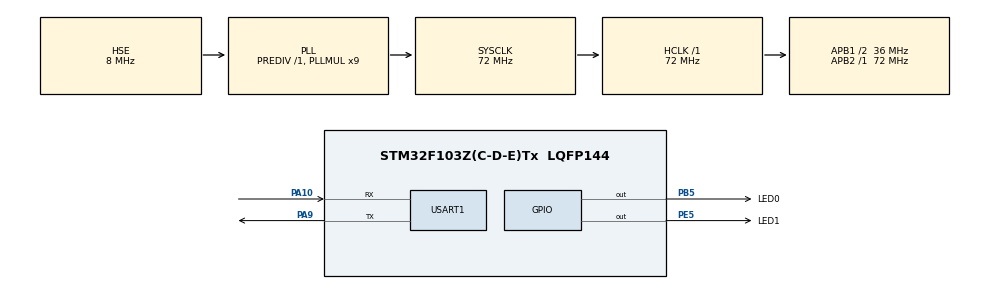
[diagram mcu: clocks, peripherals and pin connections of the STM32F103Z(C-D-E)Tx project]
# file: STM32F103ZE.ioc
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FREERTOS.Tasks01=Task_LED0,0,128,Func_LED0,Default,NULL,Dynamic,NULL,NULL;Task_LED1,-3,128,Func_LED1,Default,NULL,Dynamic,NULL,NULL
Mcu.Family=STM32F1
Mcu.Name=STM32F103Z(C-D-E)Tx
Mcu.Package=LQFP144
NVIC.FLASH_IRQn=true\:5\:0\:false\:true\:true\:1\:true\:true
NVIC.PVD_IRQn=true\:5\:0\:false\:true\:true\:4\:true\:true
NVIC.PriorityGroup=NVIC_PRIORITYGROUP_4
NVIC.RCC_IRQn=true\:5\:0\:true\:true\:true\:2\:true\:true
NVIC.TIM8_UP_IRQn=true\:0\:0\:false\:false\:true\:false\:false
NVIC.TimeBase=TIM8_UP_IRQn
NVIC.TimeBaseIP=TIM8
NVIC.USART1_IRQn=true\:5\:0\:false\:true\:true\:3\:true\:true
OSC_IN.Mode=HSE-External-Oscillator
OSC_IN.Signal=RCC_OSC_IN
OSC_OUT.Mode=HSE-External-Oscillator
OSC_OUT.Signal=RCC_OSC_OUT
PA10.Mode=Asynchronous
PA10.Signal=USART1_RX
PA13.Mode=Serial_Wire
PA13.Signal=SYS_JTMS-SWDIO
PA14.Mode=Serial_Wire
PA14.Signal=SYS_JTCK-SWCLK
PA9.Mode=Asynchronous
PA9.Signal=USART1_TX
PB5.GPIO_Label=LED0
PB5.GPIO_Speed=GPIO_SPEED_FREQ_LOW
PB5.Signal=GPIO_Output
PC14-OSC32_IN.Mode=LSE-External-Oscillator
PC14-OSC32_IN.Signal=RCC_OSC32_IN
PC15-OSC32_OUT.Mode=LSE-External-Oscillator
PC15-OSC32_OUT.Signal=RCC_OSC32_OUT
PE5.GPIO_Label=LED1
PE5.Signal=GPIO_Output
ProjectManager.HeapSize=0x200
ProjectManager.StackSize=0x400
ProjectManager.TargetToolchain=MDK-ARM V5
RCC.AHBFreq_Value=72000000
RCC.APB1CLKDivider=RCC_HCLK_DIV2
RCC.APB1Freq_Value=36000000
RCC.APB1TimFreq_Value=72000000
RCC.APB2Freq_Value=72000000
RCC.APB2TimFreq_Value=72000000
RCC.HCLKFreq_Value=72000000
RCC.PLLMUL=RCC_PLL_MUL9
RCC.PLLSourceVirtual=RCC_PLLSOURCE_HSE
RCC.SYSCLKFreq_VALUE=72000000
RCC.SYSCLKSource=RCC_SYSCLKSOURCE_PLLCLK
RCC.USBFreq_Value=72000000
USART1.VirtualMode=VM_ASYNC
VP_FREERTOS_VS_ENABLE.Mode=Enabled
VP_SYS_VS_tim8.Mode=TIM8
board=custom

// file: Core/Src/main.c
/* USER CODE BEGIN Header */
/**
  ******************************************************************************
  * @file           : main.c
  * @brief          : Main program body
  ******************************************************************************
  ** This notice applies to any and all portions of this file
  * that are not between comment pairs USER CODE BEGIN and
  * USER CODE END. Other portions of this file, whether
  * inserted by the user or by software development tools
  * are owned by their respective copyright owners.
  *
  * COPYRIGHT(c) 2019 STMicroelectronics
  *
  * Redistribution and use in source and binary forms, with or without modification,
  * are permitted provided that the following conditions are met:
  *   1. Redistributions of source code must retain the above copyright notice,
  *      this list of conditions and the following disclaimer.
  *   2. Redistributions in binary form must reproduce the above copyright notice,
  *      this list of conditions and the following disclaimer in the documentation
  *      and/or other materials provided with the distribution.
  *   3. Neither the name of STMicroelectronics nor the names of its contributors
  *      may be used to endorse or promote products derived from this software
  *      without specific prior written permission.
  *
  * THIS SOFTWARE IS PROVIDED BY THE COPYRIGHT HOLDERS AND CONTRIBUTORS "AS IS"
  * AND ANY EXPRESS OR IMPLIED WARRANTIES, INCLUDING, BUT NOT LIMITED TO, THE
  * IMPLIED WARRANTIES OF MERCHANTABILITY AND FITNESS FOR A PARTICULAR PURPOSE ARE
  * DISCLAIMED. IN NO EVENT SHALL THE COPYRIGHT HOLDER OR CONTRIBUTORS BE LIABLE
  * FOR ANY DIRECT, INDIRECT, INCIDENTAL, SPECIAL, EXEMPLARY, OR CONSEQUENTIAL
  * DAMAGES (INCLUDING, BUT NOT LIMITED TO, PROCUREMENT OF SUBSTITUTE GOODS OR
  * SERVICES; LOSS OF USE, DATA, OR PROFITS; OR BUSINESS INTERRUPTION) HOWEVER
  * CAUSED AND ON ANY THEORY OF LIABILITY, WHETHER IN CONTRACT, STRICT LIABILITY,
  * OR TORT (INCLUDING NEGLIGENCE OR OTHERWISE) ARISING IN ANY WAY OUT OF THE USE
  * OF THIS SOFTWARE, EVEN IF ADVISED OF THE POSSIBILITY OF SUCH DAMAGE.
  *
  ******************************************************************************
  */
/* USER CODE END Header */

#include "main.h"
#include "cmsis_os.h"
#include "usart.h"
#include "gpio.h"

void SystemClock_Config(void);
void MX_FREERTOS_Init(void);
static void MX_NVIC_Init(void);

int main(void)
{

  /* MCU Configuration--------------------------------------------------------*/

  /* Reset of all peripherals, Initializes the Flash interface and the Systick. */
  HAL_Init();

  /* Configure the system clock */
  SystemClock_Config();

  /* Initialize all configured peripherals */
  MX_GPIO_Init();
  MX_USART1_UART_Init();

  /* Initialize interrupts */
  MX_NVIC_Init();
  /* USER CODE BEGIN 2 */
	HAL_UART_Receive_IT(&huart1,&Buffer_huart1[0],1);
  /* USER CODE END 2 */

  /* Call init function for freertos objects (in freertos.c) */
  MX_FREERTOS_Init();

  /* Start scheduler */
  osKernelStart();

  /* We should never get here as control is now taken by the scheduler */

  /* Infinite loop */
  while (1)
  {

  }
}

void SystemClock_Config(void)
{
  RCC_OscInitTypeDef RCC_OscInitStruct = {0};
  RCC_ClkInitTypeDef RCC_ClkInitStruct = {0};

  /**Initializes the CPU, AHB and APB busses clocks
  */
  RCC_OscInitStruct.OscillatorType = RCC_OSCILLATORTYPE_HSE;
  RCC_OscInitStruct.HSEState = RCC_HSE_ON;
  RCC_OscInitStruct.HSEPredivValue = RCC_HSE_PREDIV_DIV1;
  RCC_OscInitStruct.HSIState = RCC_HSI_ON;
  RCC_OscInitStruct.PLL.PLLState = RCC_PLL_ON;
  RCC_OscInitStruct.PLL.PLLSource = RCC_PLLSOURCE_HSE;
  RCC_OscInitStruct.PLL.PLLMUL = RCC_PLL_MUL9;
  if (HAL_RCC_OscConfig(&RCC_OscInitStruct) != HAL_OK)
  {
    Error_Handler();
  }
  /**Initializes the CPU, AHB and APB busses clocks
  */
  RCC_ClkInitStruct.ClockType = RCC_CLOCKTYPE_HCLK|RCC_CLOCKTYPE_SYSCLK
                              |RCC_CLOCKTYPE_PCLK1|RCC_CLOCKTYPE_PCLK2;
  RCC_ClkInitStruct.SYSCLKSource = RCC_SYSCLKSOURCE_PLLCLK;
  RCC_ClkInitStruct.AHBCLKDivider = RCC_SYSCLK_DIV1;
  RCC_ClkInitStruct.APB1CLKDivider = RCC_HCLK_DIV2;
  RCC_ClkInitStruct.APB2CLKDivider = RCC_HCLK_DIV1;

  if (HAL_RCC_ClockConfig(&RCC_ClkInitStruct, FLASH_LATENCY_2) != HAL_OK)
  {
    Error_Handler();
  }
}

/**
  * @brief NVIC Configuration.
  * @retval None
  */
static void MX_NVIC_Init(void)
{
  /* RCC_IRQn interrupt configuration */
  HAL_NVIC_SetPriority(RCC_IRQn, 5, 0);
  HAL_NVIC_EnableIRQ(RCC_IRQn);
  /* FLASH_IRQn interrupt configuration */
  HAL_NVIC_SetPriority(FLASH_IRQn, 5, 0);
  HAL_NVIC_EnableIRQ(FLASH_IRQn);
  /* PVD_IRQn interrupt configuration */
  HAL_NVIC_SetPriority(PVD_IRQn, 5, 0);
  HAL_NVIC_EnableIRQ(PVD_IRQn);
}

void HAL_TIM_PeriodElapsedCallback(TIM_HandleTypeDef *htim)
{
  if (htim->Instance == TIM8) {
    HAL_IncTick();
  }
}

void Error_Handler(void)
{
}

/************************ (C) COPYRIGHT STMicroelectronics *****END OF FILE****/

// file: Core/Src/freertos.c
/* USER CODE BEGIN Header */
/**
  ******************************************************************************
  * File Name          : freertos.c
  * Description        : Code for freertos applications
  ******************************************************************************
  * This notice applies to any and all portions of this file
  * that are not between comment pairs USER CODE BEGIN and
  * USER CODE END. Other portions of this file, whether
  * inserted by the user or by software development tools
  * are owned by their respective copyright owners.
  *
  * Copyright (c) 2019 STMicroelectronics International N.V.
  * All rights reserved.
  *
  * Redistribution and use in source and binary forms, with or without
  * modification, are permitted, provided that the following conditions are met:
  *
  * 1. Redistribution of source code must retain the above copyright notice,
  *    this list of conditions and the following disclaimer.
  * 2. Redistributions in binary form must reproduce the above copyright notice,
  *    this list of conditions and the following disclaimer in the documentation
  *    and/or other materials provided with the distribution.
  * 3. Neither the name of STMicroelectronics nor the names of other
  *    contributors to this software may be used to endorse or promote products
  *    derived from this software without specific written permission.
  * 4. This software, including modifications and/or derivative works of this
  *    software, must execute solely and exclusively on microcontroller or
  *    microprocessor devices manufactured by or for STMicroelectronics.
  * 5. Redistribution and use of this software other than as permitted under
  *    this license is void and will automatically terminate your rights under
  *    this license.
  *
  * THIS SOFTWARE IS PROVIDED BY STMICROELECTRONICS AND CONTRIBUTORS "AS IS"
  * AND ANY EXPRESS, IMPLIED OR STATUTORY WARRANTIES, INCLUDING, BUT NOT
  * LIMITED TO, THE IMPLIED WARRANTIES OF MERCHANTABILITY, FITNESS FOR A
  * PARTICULAR PURPOSE AND NON-INFRINGEMENT OF THIRD PARTY INTELLECTUAL PROPERTY
  * RIGHTS ARE DISCLAIMED TO THE FULLEST EXTENT PERMITTED BY LAW. IN NO EVENT
  * SHALL STMICROELECTRONICS OR CONTRIBUTORS BE LIABLE FOR ANY DIRECT, INDIRECT,
  * INCIDENTAL, SPECIAL, EXEMPLARY, OR CONSEQUENTIAL DAMAGES (INCLUDING, BUT NOT
  * LIMITED TO, PROCUREMENT OF SUBSTITUTE GOODS OR SERVICES; LOSS OF USE, DATA,
  * OR PROFITS; OR BUSINESS INTERRUPTION) HOWEVER CAUSED AND ON ANY THEORY OF
  * LIABILITY, WHETHER IN CONTRACT, STRICT LIABILITY, OR TORT (INCLUDING
  * NEGLIGENCE OR OTHERWISE) ARISING IN ANY WAY OUT OF THE USE OF THIS SOFTWARE,
  * EVEN IF ADVISED OF THE POSSIBILITY OF SUCH DAMAGE.
  *
  ******************************************************************************
  */
/* USER CODE END Header */

#include "FreeRTOS.h"
#include "task.h"
#include "main.h"
#include "cmsis_os.h"

osThreadId Task_LED0Handle;
osThreadId Task_LED1Handle;

void Func_LED0(void const * argument);
void Func_LED1(void const * argument);

void MX_FREERTOS_Init(void); /* (MISRA C 2004 rule 8.1) */

void MX_FREERTOS_Init(void) {

  /* Create the thread(s) */
  /* definition and creation of Task_LED0 */
  osThreadDef(Task_LED0, Func_LED0, osPriorityNormal, 0, 128);
  Task_LED0Handle = osThreadCreate(osThread(Task_LED0), NULL);

  /* definition and creation of Task_LED1 */
  osThreadDef(Task_LED1, Func_LED1, osPriorityIdle, 0, 128);
  Task_LED1Handle = osThreadCreate(osThread(Task_LED1), NULL);

}

void Func_LED0(void const * argument)
{

  /* USER CODE BEGIN Func_LED0 */
  /* Infinite loop */
  for(;;)
  {
    osDelay(500);
		printf("hello!");
		HAL_GPIO_TogglePin(LED0_GPIO_Port,LED0_Pin);
  }
  /* USER CODE END Func_LED0 */
}

void Func_LED1(void const * argument)
{
  /* USER CODE BEGIN Func_LED1 */
  /* Infinite loop */
  for(;;)
  {
    osDelay(50);
		HAL_GPIO_TogglePin(LED1_GPIO_Port,LED1_Pin);
  }
  /* USER CODE END Func_LED1 */
}

/************************ (C) COPYRIGHT STMicroelectronics *****END OF FILE****/
